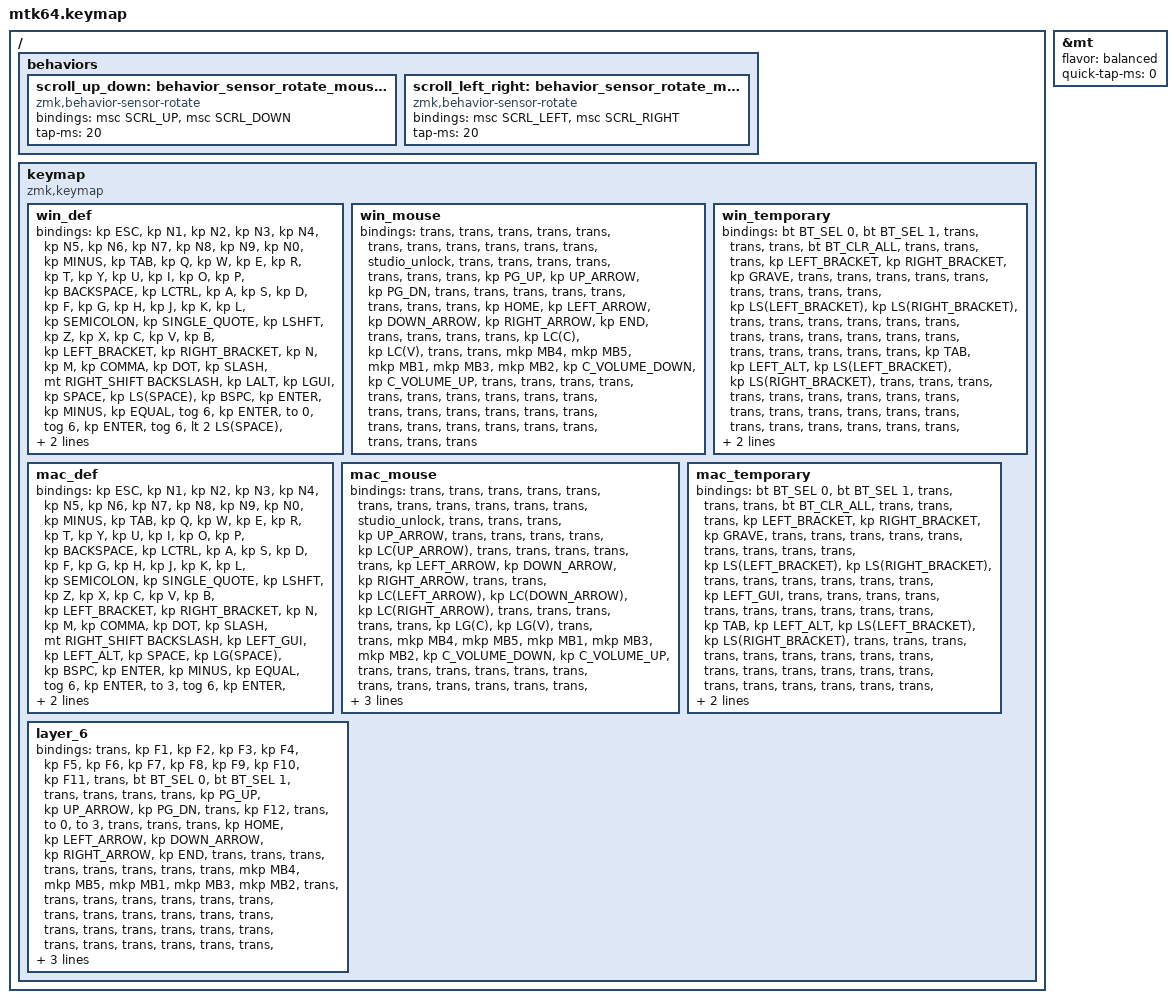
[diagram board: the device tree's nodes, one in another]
#include "keycode_japanese.h"
#include <behaviors.dtsi>
#include <dt-bindings/zmk/bt.h>
#include <dt-bindings/zmk/keys.h>
#include <dt-bindings/zmk/pointing.h>

// スクロール量の設定

#define ZMK_POINTING_DEFAULT_SCRL_VAL 100

&mt {
    flavor = "balanced";
    quick-tap-ms = <0>;
};

/ {
    behaviors {
        // 垂直スクロール用のbehaviorの設定

        scroll_up_down: behavior_sensor_rotate_mouse_wheel_up_down {
            compatible = "zmk,behavior-sensor-rotate";
            #sensor-binding-cells = <0>;
            bindings = <&msc SCRL_UP>, <&msc SCRL_DOWN>;

            tap-ms = <20>; // スクロールのタップ時間
        };

        // 水平スクロール用のbehaviorの設定

        scroll_left_right: behavior_sensor_rotate_mouse_wheel_left_right {
            compatible = "zmk,behavior-sensor-rotate";
            #sensor-binding-cells = <0>;
            bindings = <&msc SCRL_LEFT>, <&msc SCRL_RIGHT>;

            tap-ms = <20>; // スクロールのタップ時間
        };
    };
};

/ {
    keymap {
        compatible = "zmk,keymap";

        win_def {
            bindings = <
&kp ESC  &kp N1  &kp N2  &kp N3  &kp N4  &kp N5  &kp N6  &kp N7  &kp N8  &kp N9  &kp N0  &kp MINUS  &kp TAB  &kp Q  &kp W  &kp E  &kp R  &kp T  &kp Y  &kp U  &kp I  &kp O  &kp P  &kp BACKSPACE  &kp LCTRL  &kp A  &kp S  &kp D  &kp F  &kp G  &kp H  &kp J  &kp K  &kp L  &kp SEMICOLON  &kp SINGLE_QUOTE  &kp LSHFT  &kp Z  &kp X  &kp C  &kp V  &kp B  &kp LEFT_BRACKET  &kp RIGHT_BRACKET  &kp N  &kp M  &kp COMMA  &kp DOT  &kp SLASH  &mt RIGHT_SHIFT BACKSLASH  &kp LALT  &kp LGUI  &kp SPACE  &kp LS(SPACE)  &kp BSPC  &kp ENTER  &kp MINUS  &kp EQUAL  &tog 6  &kp ENTER  &to 0  &tog 6  &kp ENTER  &tog 6  &lt 2 LS(SPACE)  &tog 1  &mo 1  &mo 6  &mo 2  &mo 1  &mo 6  &mo 2  &mo 1  &mo 6  &mo 2
            >;
        };

        win_mouse {
            bindings = <
&trans  &trans  &trans  &trans  &trans  &trans  &trans  &trans  &trans  &trans  &trans  &studio_unlock  &trans  &trans  &trans  &trans  &trans  &trans  &trans  &kp PG_UP  &kp UP_ARROW  &kp PG_DN  &trans  &trans  &trans  &trans  &trans  &trans  &trans  &trans  &kp HOME  &kp LEFT_ARROW  &kp DOWN_ARROW  &kp RIGHT_ARROW  &kp END  &trans  &trans  &trans  &trans  &kp LC(C)  &kp LC(V)  &trans  &trans  &mkp MB4  &mkp MB5  &mkp MB1  &mkp MB3  &mkp MB2  &kp C_VOLUME_DOWN  &kp C_VOLUME_UP  &trans  &trans  &trans  &trans  &trans  &trans  &trans  &trans  &trans  &trans  &trans  &trans  &trans  &trans  &trans  &trans  &trans  &trans  &trans  &trans  &trans  &trans  &trans  &trans  &trans
            >;
        };

        win_temporary {
            bindings = <
&bt BT_SEL 0  &bt BT_SEL 1  &trans  &trans  &trans  &bt BT_CLR_ALL  &trans  &trans  &trans  &kp LEFT_BRACKET  &kp RIGHT_BRACKET  &kp GRAVE  &trans  &trans  &trans  &trans  &trans  &trans  &trans  &trans  &trans  &kp LS(LEFT_BRACKET)  &kp LS(RIGHT_BRACKET)  &trans  &trans  &trans  &trans  &trans  &trans  &trans  &trans  &trans  &trans  &trans  &trans  &trans  &trans  &trans  &trans  &trans  &kp TAB  &kp LEFT_ALT  &kp LS(LEFT_BRACKET)  &kp LS(RIGHT_BRACKET)  &trans  &trans  &trans  &trans  &trans  &trans  &trans  &trans  &trans  &trans  &trans  &trans  &trans  &trans  &trans  &trans  &trans  &trans  &trans  &trans  &trans  &trans  &trans  &trans  &trans  &trans  &trans  &trans  &trans  &trans  &trans
            >;
        };

        mac_def {
            bindings = <
&kp ESC  &kp N1  &kp N2  &kp N3  &kp N4  &kp N5  &kp N6  &kp N7  &kp N8  &kp N9  &kp N0  &kp MINUS  &kp TAB  &kp Q  &kp W  &kp E  &kp R  &kp T  &kp Y  &kp U  &kp I  &kp O  &kp P  &kp BACKSPACE  &kp LCTRL  &kp A  &kp S  &kp D  &kp F  &kp G  &kp H  &kp J  &kp K  &kp L  &kp SEMICOLON  &kp SINGLE_QUOTE  &kp LSHFT  &kp Z  &kp X  &kp C  &kp V  &kp B  &kp LEFT_BRACKET  &kp RIGHT_BRACKET  &kp N  &kp M  &kp COMMA  &kp DOT  &kp SLASH  &mt RIGHT_SHIFT BACKSLASH  &kp LEFT_GUI  &kp LEFT_ALT  &kp SPACE  &kp LG(SPACE)  &kp BSPC  &kp ENTER  &kp MINUS  &kp EQUAL  &tog 6  &kp ENTER  &to 3  &tog 6  &kp ENTER  &tog 6  &lt 5 LG(SPACE)  &tog 4  &mo 4  &mo 6  &mo 5  &mo 4  &mo 6  &mo 5  &mo 4  &mo 6  &mo 5
            >;
        };

        mac_mouse {
            bindings = <
&trans  &trans  &trans  &trans  &trans  &trans  &trans  &trans  &trans  &trans  &trans  &studio_unlock  &trans  &trans  &trans  &kp UP_ARROW  &trans  &trans  &trans  &trans  &kp LC(UP_ARROW)  &trans  &trans  &trans  &trans  &trans  &kp LEFT_ARROW  &kp DOWN_ARROW  &kp RIGHT_ARROW  &trans  &trans  &kp LC(LEFT_ARROW)  &kp LC(DOWN_ARROW)  &kp LC(RIGHT_ARROW)  &trans  &trans  &trans  &trans  &trans  &kp LG(C)  &kp LG(V)  &trans  &trans  &mkp MB4  &mkp MB5  &mkp MB1  &mkp MB3  &mkp MB2  &kp C_VOLUME_DOWN  &kp C_VOLUME_UP  &trans  &trans  &trans  &trans  &trans  &trans  &trans  &trans  &trans  &trans  &trans  &trans  &trans  &trans  &trans  &trans  &trans  &trans  &trans  &trans  &trans  &trans  &trans  &trans  &trans
            >;
        };

        mac_temporary {
            bindings = <
&bt BT_SEL 0  &bt BT_SEL 1  &trans  &trans  &trans  &bt BT_CLR_ALL  &trans  &trans  &trans  &kp LEFT_BRACKET  &kp RIGHT_BRACKET  &kp GRAVE  &trans  &trans  &trans  &trans  &trans  &trans  &trans  &trans  &trans  &kp LS(LEFT_BRACKET)  &kp LS(RIGHT_BRACKET)  &trans  &trans  &trans  &trans  &trans  &trans  &kp LEFT_GUI  &trans  &trans  &trans  &trans  &trans  &trans  &trans  &trans  &trans  &trans  &kp TAB  &kp LEFT_ALT  &kp LS(LEFT_BRACKET)  &kp LS(RIGHT_BRACKET)  &trans  &trans  &trans  &trans  &trans  &trans  &trans  &trans  &trans  &trans  &trans  &trans  &trans  &trans  &trans  &trans  &trans  &trans  &trans  &trans  &trans  &trans  &trans  &trans  &trans  &trans  &trans  &trans  &trans  &trans  &trans
            >;
        };

        layer_6 {
            bindings = <
&trans  &kp F1  &kp F2  &kp F3  &kp F4  &kp F5  &kp F6  &kp F7  &kp F8  &kp F9  &kp F10  &kp F11  &trans  &bt BT_SEL 0  &bt BT_SEL 1  &trans  &trans  &trans  &trans  &kp PG_UP  &kp UP_ARROW  &kp PG_DN  &trans  &kp F12  &trans  &to 0  &to 3  &trans  &trans  &trans  &kp HOME  &kp LEFT_ARROW  &kp DOWN_ARROW  &kp RIGHT_ARROW  &kp END  &trans  &trans  &trans  &trans  &trans  &trans  &trans  &trans  &mkp MB4  &mkp MB5  &mkp MB1  &mkp MB3  &mkp MB2  &trans  &trans  &trans  &trans  &trans  &trans  &trans  &trans  &trans  &trans  &trans  &trans  &trans  &trans  &trans  &trans  &trans  &trans  &trans  &trans  &trans  &trans  &trans  &trans  &trans  &trans  &trans
            >;

            sensor-bindings = <
                &inc_dec_kp TAB LC(TAB) 
                &inc_dec_kp PG_UP PG_DN
            >;
        };
    };
};
